# STM32MP13xx register map
File version: 1.7
CPU: CA7 r0p0, little endian, MPU, FPU, 4 interrupt priority bits
Registers are 32-bit, read-write, reset 0x0 unless marked. A register's access mark holds for its fields unless they carry their own. Offsets are from the block's base; [hi:lo] are bit positions; lines under a group give offsets from that group; 'fields as' and 'values as' point back to an identical list.

## DCMIPP — DCMIPP register block
Base 0x5A000000
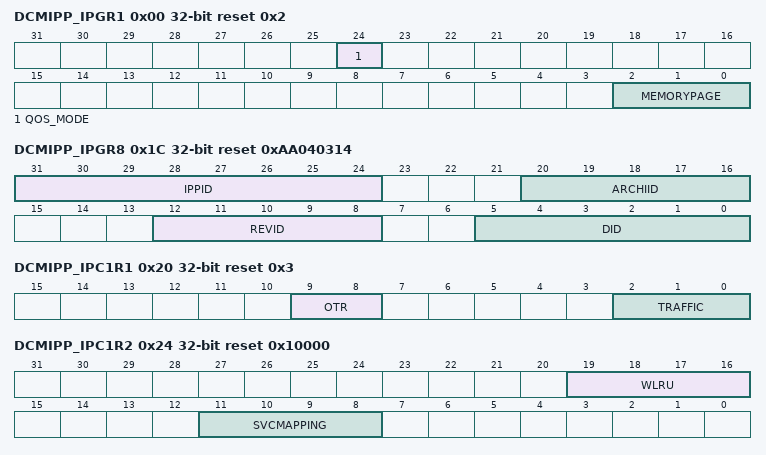
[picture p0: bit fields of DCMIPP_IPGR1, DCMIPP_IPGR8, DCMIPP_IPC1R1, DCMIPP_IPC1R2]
0x00 DCMIPP_IPGR1 reset 0x2 — DCMIPP IP-Plug global register 1
  [24] QOS_MODE — Quality of service
  [2:0] MEMORYPAGE — Memory page size, as power of 2 of 64-byte units:
    0=64 bytes; 1=128 bytes
0x04 DCMIPP_IPGR2 — DCMIPP IP-Plug global register 2
  [0] PSTART — Request to lock the IP-Plug, to allow reconfiguration.
    0=No lock requested, IP-Plug runs on demand by background HW; 1=Lock requested: IP-Plug freezes shortly (see IDLE bit when lock is active)
0x08 DCMIPP_IPGR3 ro reset 0x1 — DCMIPP IP-Plug global register 3
  [0] IDLE — Status of IP-Plug
    0=IP-Plug is running (on demand by background HW); 1=IP-Plug is currently locked and can be reconfigured
0x1C DCMIPP_IPGR8 ro reset 0xAA040314 — DCMIPP IP-Plug identification register
  [31:24] IPPID — IP identifier (0xAA)
  [20:16] ARCHIID — Architecture identifier (0x04)
  [12:8] REVID — Revision identifier (0x03)
  [5:0] DID — Division identifier (0x14)
0x20 DCMIPP_IPC1R1 reset 0x3 — DCMIPP IP-Plug Clientx register 1
  [9:8] OTR — Maximum outstanding transactions
    0=Disabled; 1=Maximum two outstanding transactions ongoing
  [2:0] TRAFFIC — Burst size as power of 2 of 8-byte units
    0=8 bytes; 1=16 bytes
0x24 DCMIPP_IPC1R2 reset 0x10000 — DCMIPP IP-Plug Clientx register 2
  [19:16] WLRU — Ratio for WLRU[3:0] arbitration
    0=Ratio part = 1; 1=Ratio part = 2
  [11:8] SVCMAPPING — Non-user, must be kept at reset value.
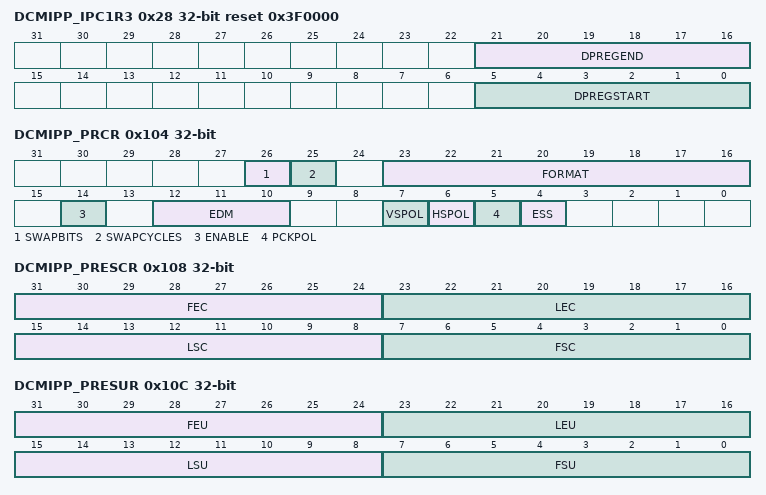
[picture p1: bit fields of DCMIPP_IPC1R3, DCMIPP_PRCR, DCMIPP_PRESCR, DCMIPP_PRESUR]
0x28 DCMIPP_IPC1R3 reset 0x3F0000 — DCMIPP IP-Plug Clientx register 3
  [21:16] DPREGEND — End word (AXI width = 64 bits) of the FIFO of Clientx.
  [5:0] DPREGSTART — Start word (AXI width = 64 bits) of the FIFO of Clientx.
0x104 DCMIPP_PRCR — DCMIPP parallel interface control register
  [26] SWAPBITS — Swap LSB vs.
    0=As received; 1=Swapped MSB vs
  [25] SWAPCYCLES — Swap data (cycle 0 vs.
    0=Default; 1=Swap active: the data of cycle 1 is used before the data of cycle 0
  [23:16] FORMAT — Other values: data are captured and output as-is only through the data/dump pipeline (for example JPEG or byte input format).
    30=YUV422; 34=RGB565; 36=RGB888 (= YUV444); 42=RAW8; 43=RAW10; 44=RAW12; 45=RAW14; 74=monochrome 8-bit; 75=monochrome 10-bit; 76=monochrome 12-bit; 77=monochrome 14-bit; 90=byte stream (JPEG, compressed video)
  [14] ENABLE — Parallel interface enable
    0=Parallel interface disabled to lower power consumption; 1=Parallel interface enabled
  [12:10] EDM — Extended data mode
    0=Interface captures 8-bit data on every pixel clock; 1=Interface captures 10-bit data on every pixel clock; 2=Interface captures 12-bit data on every pixel clock; 3=Interface captures 14-bit data on every pixel clock; 4=Interface captures 16-bit data on every pixel clock
  [7] VSPOL — Vertical synchronization polarity
    0=VSYNC active low; 1=VSYNC active high
  [6] HSPOL — Horizontal synchronization polarity
    0=HSYNC active low; 1=HSYNC active high
  [5] PCKPOL — Pixel clock polarity
    0=Falling edge active; 1=Rising edge active
  [4] ESS — Embedded synchronization select
    0=Hardware synchronization data capture (frame/line start/stop) is synchronized with the HSYNC/VSYNC signals; 1=Embedded synchronization data capture is synchronized with synchronization codes embedded in the data flow
0x108 DCMIPP_PRESCR — DCMIPP parallel interface embedded synchronization code register
  [31:24] FEC — Frame end delimiter code
  [23:16] LEC — Line end delimiter code
  [15:8] LSC — Line start delimiter code
  [7:0] FSC — Frame start delimiter code
0x10C DCMIPP_PRESUR — DCMIPP parallel interface embedded synchronization unmask register
  [31:24] FEU — Frame end delimiter unmask
    0=The corresponding bit in the FEC byte in DCMIPP_ESCR is masked while comparing the frame end delimiter with the received data; 1=The corresponding bit in the FEC byte in DCMIPP_ESCR is compared while comparing the frame end delimiter with the received data
  [23:16] LEU — Line end delimiter unmask
    0=The corresponding bit in the LEC byte in DCMIPP_ESCR is masked while comparing the line end delimiter with the received data; 1=The corresponding bit in the LEC byte in DCMIPP_ESCR is compared while comparing the line end delimiter with the received data
  [15:8] LSU — Line start delimiter unmask
    0=The corresponding bit in the LSC byte in DCMIPP_ESCR is masked while comparing the line start delimiter with the received data; 1=The corresponding bit in the LSC byte in DCMIPP_ESCR is compared while comparing the line start delimiter with the received data
  [7:0] FSU — Frame start delimiter unmask
    0=The corresponding bit in the FSC byte in DCMIPP_ESCR is masked while comparing the frame start delimiter with the received data; 1=The corresponding bit in the FSC byte in DCMIPP_ESCR is compared while comparing the frame start delimiter with the received data
0x1F4 DCMIPP_PRIER — DCMIPP parallel interface interrupt enable register
  [6] ERRIE — Synchronization error interrupt enable
    0=No interrupt generation; 1=An interrupt is generated if the embedded synchronization codes are not received in the correct order
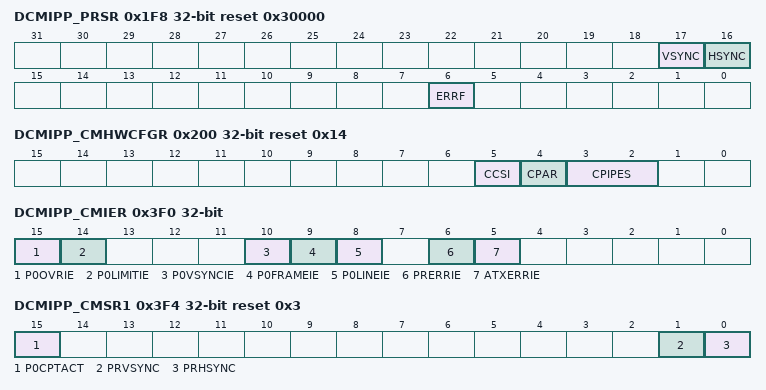
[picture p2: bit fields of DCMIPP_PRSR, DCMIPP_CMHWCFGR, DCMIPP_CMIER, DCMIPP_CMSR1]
0x1F8 DCMIPP_PRSR ro reset 0x30000 — DCMIPP parallel interface status register
  [17] VSYNC — This bit gives the state of the VSYNC pin with the correct programmed polarity if ENABLE bit is set into the DCMIPP_PRCR register and if the pixel clock is received.
    0=Active frame; 1=Synchronization between frames
  [16] HSYNC — This bit gives the state of the HSYNC pin with the correct programmed polarity if ENABLE bit is set into the DCMIPP_PRCR register and if the pixel clock is received.
    0=Active line; 1=Synchronization between lines
  [6] ERRF — Synchronization error raw interrupt status
    0=No synchronization error detected; 1=Embedded synchronization characters are not received in the correct order
0x1FC DCMIPP_PRFCR wo — DCMIPP parallel interface interrupt clear register
  [6] CERRF — Synchronization error interrupt status clear
0x200 DCMIPP_CMHWCFGR ro reset 0x14 — DCMIPP common IP HW configuration register
  [5] CCSI — Presence of the CSI-2 host interface:
    0=No input from CSI-2 host; 1=Input from CSI-2 host is implemented (independently from the presence of CSI-2 host)
  [4] CPAR — Presence of the parallel interface:
    0=Parallel interface input is not implemented; 1=Parallel interface input is implemented
  [3:2] CPIPES — Amount of instantiated pipes (either dump or pixel pipes)
0x204 DCMIPP_CMCR wo — DCMIPP common configuration register
  [4] CFC — Clear frame counter
0x208 DCMIPP_CMFRCR ro — DCMIPP common frame counter register
  [31:0] FRMCNT — Frame counter, read-only, loops around.
0x3F0 DCMIPP_CMIER — DCMIPP common interrupt enable register
  [all] fields
    0=No interrupt generation; 1=An interrupt is generated
  [15] P0OVRIE — Overrun interrupt enable for Pipe0
  [14] P0LIMITIE — Limit interrupt enable for Pipe0
  [10] P0VSYNCIE — Vertical sync interrupt enable for Pipe0
  [9] P0FRAMEIE — Frame capture complete interrupt enable for Pipe0
  [8] P0LINEIE — Multi-line capture complete interrupt enable for Pipe0
  [6] PRERRIE — Limit interrupt enable for the parallel Interface
  [5] ATXERRIE — AXI transfer error interrupt enable for IP-Plug
0x3F4 DCMIPP_CMSR1 ro reset 0x3 — DCMIPP common status register 1
  [15] P0CPTACT — Active frame capture (active from start-of-frame to frame complete) for Pipe0
    0=No capture currently active; 1=Capture currently active
  [1] PRVSYNC — This bit gives the state of the VSYNC pin with the correct programmed polarity on the parallel interface if ENABLE bit is set into the DCMIPP_PRCR register and if the pixel clock is received.
    0=Active frame; 1=Synchronization between frames
  [0] PRHSYNC — This bit gives the state of the HSYNC pin with the correct programmed polarity on the parallel interface if ENABLE bit is set into the DCMIPP_PRCR register and if the pixel clock is received.
    0=Active line; 1=Synchronization between lines
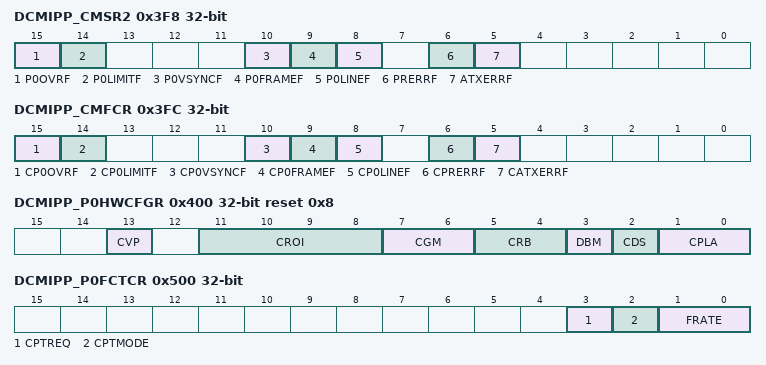
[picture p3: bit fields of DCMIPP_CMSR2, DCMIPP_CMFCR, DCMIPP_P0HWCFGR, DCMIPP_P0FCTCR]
0x3F8 DCMIPP_CMSR2 ro — DCMIPP common status register 2
  [15] P0OVRF — Overrun raw interrupt status for Pipe0
    0=No data buffer overrun occurred; 1=A data buffer overrun occurred and this frame data are corrupted
  [14] P0LIMITF — Limit raw interrupt status for Pipe0
  [10] P0VSYNCF — VSYNC raw interrupt status for Pipe0
  [9] P0FRAMEF — Frame capture completed raw interrupt status for Pipe0
    0=No capture or ongoing capture; 1=All data of a frame have been captured
  [8] P0LINEF — Multi-line capture completed raw interrupt status for Pipe0
  [6] PRERRF — Synchronization error raw interrupt status for the parallel interface.
    values as DCMIPP_PRSR.ERRF
  [5] ATXERRF — AXI transfer error interrupt status flag for the IP-Plug.
    0=No AXI transfer error detected; 1=AXI transfer error occurred on an AXI client
0x3FC DCMIPP_CMFCR wo — DCMIPP common interrupt clear register
  [15] CP0OVRF — Overrun interrupt status clear
  [14] CP0LIMITF — limit interrupt status clear
  [10] CP0VSYNCF — Vertical synchronization interrupt status clear
  [9] CP0FRAMEF — Frame capture complete interrupt status clear
  [8] CP0LINEF — Multi-line capture complete interrupt status clear
  [6] CPRERRF — Synchronization error interrupt status clear
  [5] CATXERRF — AXI transfer error interrupt status clear
0x400 DCMIPP_P0HWCFGR ro reset 0x8 — DCMIPP Pipe0 HW configuration register
  [13] CVP — Capability for pipeline virtualization
    0=No virtualization for the pipe; 1=Virtualization mechanism implemented for the pipe
  [11:8] CROI — Capability for ROI: defines the number of ROIs in the pipe
  [7:6] CGM — Capability for gamma conversions
    0=No gamma conversion; 1=Gamma conversion with three interpolated segments
  [5:4] CRB — Capability for demosaicing
    0=No demosaicing; 1=Demosaicing with 2018-03 algorithm (Matrix 3 x 3 with Edge/LineHV/Peak)
  [3] DBM — Double buffer mode
    0=No Double buffer mode supported; 1=Double buffer mode supported
  [2] CDS — Capability for downsize filter
    0=No downsize filter, basic decimation instead; 1=Downsize filter based on a BoxFilter
  [1:0] CPLA — Capability for planar buffers
    0=Capability to dump to a coplanar buffer only; 1=Capability to dump to a semi-planar buffer (i; 2=Capability to dump to full-planar buffer (i
0x404 DCMIPP_P0FSCR — DCMIPP Pipe0 flow selection configuration register
  [31] PIPEN — Activation of PipeN
    0=Pipe disabled; 1=Pipe enabled, can start capturing with CPTMODE, CPTREQ, CPTACK
0x500 DCMIPP_P0FCTCR — DCMIPP Pipe0 flow control configuration register
  [3] CPTREQ — Capture requested
    0=Capture not requested for next frame; 1=Capture requested for next frame
  [2] CPTMODE — Capture mode
    0=Continuous grab mode - The received data are transferred into the destination memory through the AXI master; 1=Snapshot mode (single frame) - Once activated, the interface waits for the start of frame, and then transfers a single frame through the AXI master
  [1:0] FRATE — Frame capture rate control
    0=All frames are captured; 1=One out of two frames captured (50% bandwidth reduction); 2=One out of four frames captured (75% bandwidth reduction); 3=One out of eight frames captured (87% bandwidth reduction)
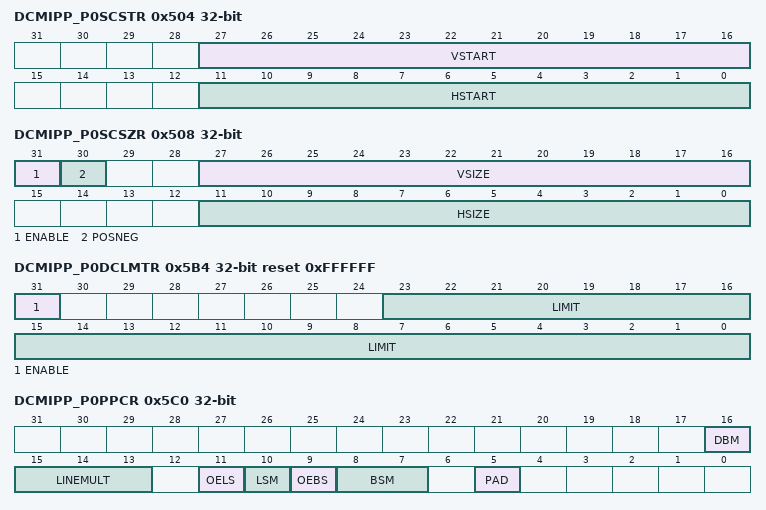
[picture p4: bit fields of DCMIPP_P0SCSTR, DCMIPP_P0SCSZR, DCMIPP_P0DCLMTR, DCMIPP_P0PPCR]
0x504 DCMIPP_P0SCSTR — DCMIPP Pipe0 statistic/crop start register
  [27:16] VSTART — Vertical start, from 0 to 4094 pixels high
  [11:0] HSTART — Horizontal start, from 0 to 4094 words wide
0x508 DCMIPP_P0SCSZR — DCMIPP Pipe0 statistic/crop size register
  [31] ENABLE — This bit is set and cleared by software.
    0=Bypass; 1=Enable
  [30] POSNEG — This bit is set and cleared by software.
    0=Positive area, the rectangle defined by VSIZE, HSIZE, and VSTART, HSTART; 1=Negative area, the area excluding the rectangle defined by VSIZE, HSIZE, and VSTART, HSTART
  [27:16] VSIZE — Vertical size, from 0 to 4094 pixels high
  [11:0] HSIZE — Horizontal size, from 0 to 4094 word wide (data 32-bit)
0x5B0 DCMIPP_P0DCCNTR ro — DCMIPP Pipe0 dump counter register
  [25:0] CNT — Number of data dumped during the frame.
0x5B4 DCMIPP_P0DCLMTR reset 0xFFFFFF — DCMIPP Pipe0 dump limit register
  [31] ENABLE
    0=Disabled, no check on the amount of 32-bit words transmitted; 1=Enabled, check done versus limit
  [23:0] LIMIT — Maximum number of 32-bit data that can be dumped during a frame, after the crop 2D operation.
0x5C0 DCMIPP_P0PPCR — DCMIPP Pipe0 pixel packer configuration register
  [16] DBM — Double buffer mode
    0=No double buffer mode activated; 1=Double buffer mode activated
  [15:13] LINEMULT — Amount of capture completed lines for LINE event and interrupt
    0=Event after one line; 1=Event after two lines; 2=Event after four lines; 3=Event after eight lines; 4=Event after sixteen lines; 5=Event after 32 lines; 6=Event after 64 lines; 7=Event after 128 lines
  [11] OELS — Odd/even line select (line select start)
    0=Interface captures first line after the frame start, second one is dropped; 1=Interface captures second line from the frame start, first one is dropped
  [10] LSM — Line select mode
    0=Interface captures all received lines; 1=Interface captures one line out of two
  [9] OEBS — Odd/even byte select (byte select start)
    0=Interface captures the first data (byte or double byte) from the frame/line start, the second one is dropped; 1=Interface captures the second data (byte or double byte) from the frame/line start, the first one is dropped
  [8:7] BSM — Byte select mode
    0=Interface captures all received data; 1=Interface captures 1 data out of 2; 2=Interface captures one byte out of four; 3=Interface captures two bytes out of four
  [5] PAD — Pad mode for monochrome and raw Bayer 10/12/14 bpp: MSB vs.
    0=Aligns on LSB (and pads null bits on MSB), for backward compatibility with former DCMI; 1=Aligns on MSB (and pads null bits on LSB), for better ease of software or GPU
0x5C4 DCMIPP_P0PPM0AR1 — DCMIPP Pipe0 pixel packer Memory0 address register 1
  [31:0] M0A — Memory0 address
0x5C8 DCMIPP_P0PPM0AR2 — DCMIPP Pipe0 pixel packer Memory0 address register 2
  [31:0] M0A — Memory0 address
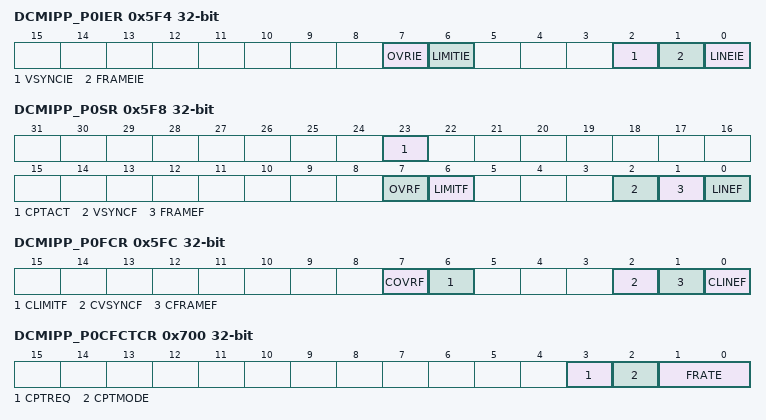
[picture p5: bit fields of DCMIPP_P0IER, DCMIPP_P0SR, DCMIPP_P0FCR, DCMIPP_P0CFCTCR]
0x5F4 DCMIPP_P0IER — DCMIPP Pipe0 interrupt enable register
  [7] OVRIE — Overrun interrupt enable
    0=No interrupt generation; 1=An interrupt is generated if the AXI master is unable to transfer the last data before new data (32-bit) are received
  [6] LIMITIE — Limit interrupt enable
    0=No interrupt generation when the limit is reached; 1=An interrupt is generated when the limit is reached
  [2] VSYNCIE — VSYNC interrupt enable
    0=No interrupt generation; 1=An interrupt is generated on each VSYNC (captured or not)
  [1] FRAMEIE — Frame capture completed interrupt enable
    0=No interrupt generation; 1=An interrupt is generated after the full capture of a cropped frame
  [0] LINEIE — Multi-line capture completed interrupt enable
    0=No interrupt generation when the line is received; 1=An interrupt is generated after the full capture of a group of lines (or last line reached)
0x5F8 DCMIPP_P0SR ro — DCMIPP Pipe0 status register
  [23] CPTACT — Capture immediate status
    0=Capture currently inactive; 1=Capture currently active
  [7] OVRF — Overrun raw interrupt status
    values as DCMIPP_CMSR2.P0OVRF
  [6] LIMITF — Limit raw interrupt status
  [2] VSYNCF — VSYNC raw interrupt status
  [1] FRAMEF — Frame capture completed raw interrupt status
    values as DCMIPP_CMSR2.P0FRAMEF
  [0] LINEF — Multi-line capture completed raw interrupt status
0x5FC DCMIPP_P0FCR wo — DCMIPP Pipe0 interrupt clear register
  [7] COVRF — Overrun interrupt status clear
  [6] CLIMITF — limit interrupt status clear
  [2] CVSYNCF — Vertical synchronization interrupt status clear
  [1] CFRAMEF — Frame capture complete interrupt status clear
  [0] CLINEF — Multi-line capture complete interrupt status clear
0x700 DCMIPP_P0CFCTCR ro — DCMIPP Pipe0 current flow control configuration register
  fields as DCMIPP_P0FCTCR
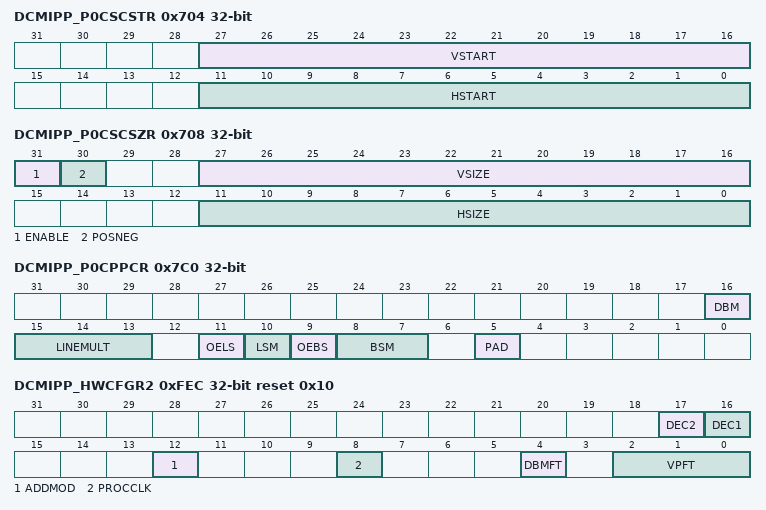
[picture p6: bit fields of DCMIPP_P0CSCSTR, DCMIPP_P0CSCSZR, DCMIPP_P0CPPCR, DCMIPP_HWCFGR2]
0x704 DCMIPP_P0CSCSTR ro — DCMIPP Pipe0 current statistic/crop start register
  [27:16] VSTART — Current vertical start, from 0 to 4094 pixels high
  [11:0] HSTART — Current horizontal start, from 0 to 4094 words wide
0x708 DCMIPP_P0CSCSZR ro — DCMIPP Pipe0 current statistic/crop size register
  [31] ENABLE — Current value of the ENABLE bit
    0=Bypass; 1=Enable: Depending on bit POSNEG value, the rectangle defined by the VSIZE, HSIZE, VSTART, HSTART can be used to extract or to remove certain amount of data (statistical extraction or removal, or basic 2D crop features)
  [30] POSNEG — Current value of the POSNEG bit
    0=Positive area; 1=Negative area
  [27:16] VSIZE — Current vertical size, from 0 to 4094 pixels high.
  [11:0] HSIZE — Current horizontal size, from 0 to 4094 word wide (data 32-bit).
0x7C0 DCMIPP_P0CPPCR ro — DCMIPP Pipe0 current pixel packer configuration register
  [16] DBM — Double buffer mode
    values as DCMIPP_P0PPCR.DBM
  [15:13] LINEMULT — Current amount of capture completed lines for LINE event and interrupt
    0=Event after every line; 1=Event after two lines; 2=Event after four lines; 3=Event after eight lines; 4=Event after sixteen lines; 5=Event after 32 lines; 6=Event after 64 lines; 7=Event after 128 lines
  [11] OELS — Current odd/even line select (ine select start)
    0=Interface captures the first line after the frame start, the second one is dropped; 1=Interface captures the second line from the frame start, the first one is dropped
  [10] LSM — Current Line select mode
    values as DCMIPP_P0PPCR.LSM
  [9] OEBS — Current odd/even byte select (byte select start)
    values as DCMIPP_P0PPCR.OEBS
  [8:7] BSM — Current Byte select mode
    0=Interface captures all received data; 1=Interface captures one data out of two; 2=Interface captures one byte out of four; 3=Interface captures two bytes out of four
  [5] PAD — Current Pad mode for monochrome and raw Bayer 10/12/14 bpp: MSB vs.
    values as DCMIPP_P0PPCR.PAD
0x7C4 DCMIPP_P0CPPM0AR1 ro — DCMIPP Pipe0 current pixel packer Memory0 address register 1
  [31:0] M0A — Memory0 address
0x7C8 DCMIPP_P0CPPM0AR2 ro — DCMIPP Pipe0 current pixel packer Memory0 address register 2
  [31:0] M0A — Memory0 address
0xFE8 DCMIPP_HWCFGR3 ro — DCMIPP hardware configuration register 3
  [0] LSF — Lens shading
0xFEC DCMIPP_HWCFGR2 ro reset 0x10 — DCMIPP hardware configuration register 2
  [17] DEC2 — Decimation on Pipe2 before downsize
    0=Decimation is not implemented; 1=Decimation is implemented
  [16] DEC1 — Decimation on Pipe1 before downsize
    0=Decimation is not implemented; 1=Decimation is implemented
  [12] ADDMOD — Address modulo computation to access a small buffer in streaming featured
    0=Address modulo is not implemented; 1=Address modulo is implemented
  [8] PROCCLK — Processing clock linked to AXI clock featured
    0=Independent processing clock not connected to AXI; 1=Processing clock is directly the AXI
  [4] DBMFT — Double buffer mode featured
  [2:0] VPFT — Virtual pipe function
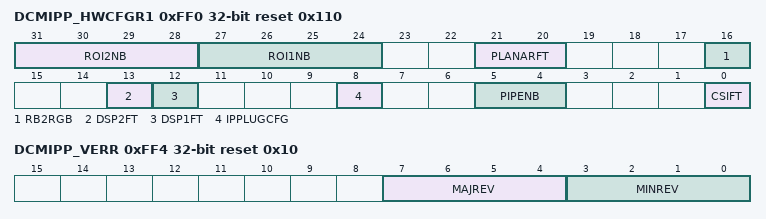
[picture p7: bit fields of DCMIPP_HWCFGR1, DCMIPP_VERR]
0xFF0 DCMIPP_HWCFGR1 ro reset 0x110 — DCMIPP hardware configuration register 1
  [31:28] ROI2NB — Number of ROIs for Pipe2
  [27:24] ROI1NB — Number of ROIs for Pipe1
  [21:20] PLANARFT — Buffer features for Pipe1
    0=Coplanar; 1=Semiplanar; 3=Full planar (one buffer per component)
  [16] RB2RGB — Raw Bayer to RGB feature (demosaicer)
  [13] DSP2FT — Down-sampling feature for the pixel Pipe2
  [12] DSP1FT — Down-sampling feature for the pixel Pipe1
  [8] IPPLUGCFG — IP-Plug configuration
  [5:4] PIPENB — Number of pipes
  [0] CSIFT — CSI2 host protocol compliant
0xFF4 DCMIPP_VERR ro reset 0x10 — DCMIPP version register
  [7:4] MAJREV — DCMIPP major revision
  [3:0] MINREV — DCMIPP minor revision
0xFF8 DCMIPP_IPIDR ro reset 0x162021 — DCMIPP identification register
  [31:0] IDR — Paralle camera interface (DCMI) and optional pixel processing (PP)
0xFFC DCMIPP_SIDR ro reset 0xA3C5DD04 — DCMIPP size identification register
  [31:0] SID — 4-Kbyte decoding space
